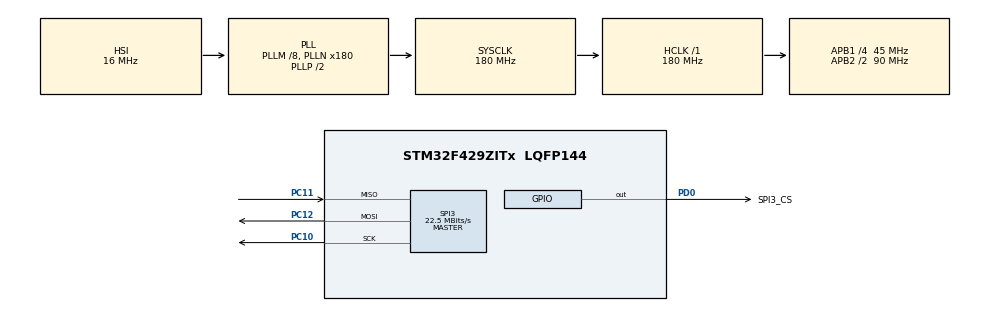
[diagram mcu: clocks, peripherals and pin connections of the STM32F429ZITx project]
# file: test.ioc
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Mcu.Family=STM32F4
Mcu.Name=STM32F429ZITx
Mcu.Package=LQFP144
NVIC.PriorityGroup=NVIC_PRIORITYGROUP_0
NVIC.SPI3_IRQn=true\:0\:0\:false\:false\:true\:true\:true\:true
PC10.Mode=Full_Duplex_Master
PC10.Signal=SPI3_SCK
PC11.Mode=Full_Duplex_Master
PC11.Signal=SPI3_MISO
PC12.Mode=Full_Duplex_Master
PC12.Signal=SPI3_MOSI
PD0.GPIO_Label=SPI3_CS
PD0.Signal=GPIO_Output
ProjectManager.HeapSize=0x200
ProjectManager.StackSize=0x400
ProjectManager.TargetToolchain=STM32CubeIDE
RCC.48MHZClocksFreq_Value=51428571.428571425
RCC.AHBFreq_Value=180000000
RCC.APB1CLKDivider=RCC_HCLK_DIV4
RCC.APB1Freq_Value=45000000
RCC.APB1TimFreq_Value=90000000
RCC.APB2CLKDivider=RCC_HCLK_DIV2
RCC.APB2Freq_Value=90000000
RCC.APB2TimFreq_Value=180000000
RCC.CortexFreq_Value=180000000
RCC.HCLKFreq_Value=180000000
RCC.HSE_VALUE=8000000
RCC.HSI_VALUE=16000000
RCC.LSE_VALUE=32768
RCC.PLLM=8
RCC.PLLN=180
RCC.PLLQ=7
RCC.SYSCLKFreq_VALUE=180000000
RCC.SYSCLKSource=RCC_SYSCLKSOURCE_PLLCLK
RCC.VCOOutputFreq_Value=360000000
SPI3.CRCCalculation=SPI_CRCCALCULATION_DISABLE
SPI3.CalculateBaudRate=22.5 MBits/s
SPI3.Direction=SPI_DIRECTION_2LINES
SPI3.Mode=SPI_MODE_MASTER
SPI3.VirtualType=VM_MASTER
board=STM32F429I-DISC1

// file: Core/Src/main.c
/* USER CODE BEGIN Header */
/**
  ******************************************************************************
  * @file           : main.c
  * @brief          : Main program body
  ******************************************************************************
  * @attention
  *
  * Copyright (c) 2025 STMicroelectronics.
  * All rights reserved.
  *
  * This software is licensed under terms that can be found in the LICENSE file
  * in the root directory of this software component.
  * If no LICENSE file comes with this software, it is provided AS-IS.
  *
  ******************************************************************************
  */
/* USER CODE END Header */
#include "main.h"
#include "spi.h"
#include "gpio.h"

/* USER CODE BEGIN Includes */
#include "DriverFactory.h"
#include "SEGGER_RTT.h"
#include "flash2click_dataType.h"
//#include "test.c"
/* USER CODE END Includes */

void SystemClock_Config(void);

int main(void)
{

  /* MCU Configuration--------------------------------------------------------*/

  /* Reset of all peripherals, Initializes the Flash interface and the Systick. */
  HAL_Init();

  /* Configure the system clock */
  SystemClock_Config();

  /* Initialize all configured peripherals */
  MX_GPIO_Init();
  MX_SPI3_Init();
  /* USER CODE BEGIN 2 */

  SEGGER_RTT_printf(0, "test string \n");

//  DriverHandle* flash2click = DriverFactory_Create(DRIVER_FLASH2CLICK);
//  sst26_flash_status status = flash2click_init(flash2click);
//
//  if(status == FLASH_ON){
//	  SEGGER_RTT_printf(0, "FLASH OK \n");
//  } else{
//	  SEGGER_RTT_printf(0, "FLASH NOT OK \n");
//  }
//
//  uint8_t data[3] = {0, 55, 244};
//
//  flash2click_chip_erase(flash2click);
//  HAL_Delay(5);
//
//  flash2click_page_program(flash2click, 0x0000000, data, 3);
//  HAL_Delay(5);
//
//  flash2click_read(flash2click, 0x0000000, data, 3);
//  HAL_Delay(5);

  flash2click_test_all_extended();

  /* USER CODE END 2 */

  /* Infinite loop */
  while (1)
  {

  }
}

void SystemClock_Config(void)
{
  RCC_OscInitTypeDef RCC_OscInitStruct = {0};
  RCC_ClkInitTypeDef RCC_ClkInitStruct = {0};

  /** Configure the main internal regulator output voltage
  */
  __HAL_RCC_PWR_CLK_ENABLE();
  __HAL_PWR_VOLTAGESCALING_CONFIG(PWR_REGULATOR_VOLTAGE_SCALE1);

  /** Initializes the RCC Oscillators according to the specified parameters
  * in the RCC_OscInitTypeDef structure.
  */
  RCC_OscInitStruct.OscillatorType = RCC_OSCILLATORTYPE_HSI;
  RCC_OscInitStruct.HSIState = RCC_HSI_ON;
  RCC_OscInitStruct.HSICalibrationValue = RCC_HSICALIBRATION_DEFAULT;
  RCC_OscInitStruct.PLL.PLLState = RCC_PLL_ON;
  RCC_OscInitStruct.PLL.PLLSource = RCC_PLLSOURCE_HSI;
  RCC_OscInitStruct.PLL.PLLM = 8;
  RCC_OscInitStruct.PLL.PLLN = 180;
  RCC_OscInitStruct.PLL.PLLP = RCC_PLLP_DIV2;
  RCC_OscInitStruct.PLL.PLLQ = 7;
  if (HAL_RCC_OscConfig(&RCC_OscInitStruct) != HAL_OK)
  {
    Error_Handler();
  }

  /** Activate the Over-Drive mode
  */
  if (HAL_PWREx_EnableOverDrive() != HAL_OK)
  {
    Error_Handler();
  }

  /** Initializes the CPU, AHB and APB buses clocks
  */
  RCC_ClkInitStruct.ClockType = RCC_CLOCKTYPE_HCLK|RCC_CLOCKTYPE_SYSCLK
                              |RCC_CLOCKTYPE_PCLK1|RCC_CLOCKTYPE_PCLK2;
  RCC_ClkInitStruct.SYSCLKSource = RCC_SYSCLKSOURCE_PLLCLK;
  RCC_ClkInitStruct.AHBCLKDivider = RCC_SYSCLK_DIV1;
  RCC_ClkInitStruct.APB1CLKDivider = RCC_HCLK_DIV4;
  RCC_ClkInitStruct.APB2CLKDivider = RCC_HCLK_DIV2;

  if (HAL_RCC_ClockConfig(&RCC_ClkInitStruct, FLASH_LATENCY_5) != HAL_OK)
  {
    Error_Handler();
  }
}

void Error_Handler(void)
{
  __disable_irq();
  while (1)
  {
  }
}
